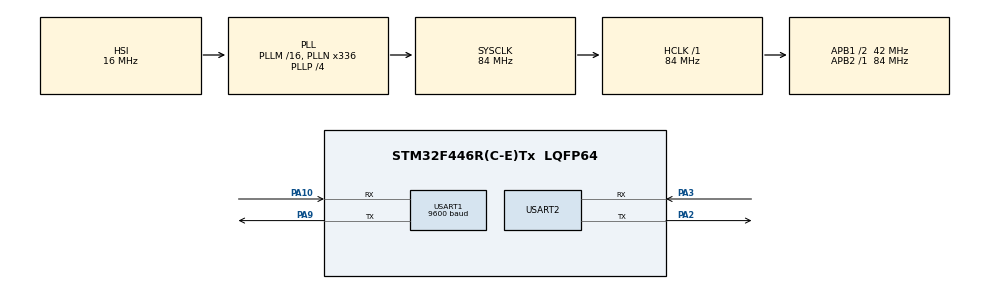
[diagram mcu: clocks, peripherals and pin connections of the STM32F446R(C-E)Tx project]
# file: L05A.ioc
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Mcu.Family=STM32F4
Mcu.Name=STM32F446R(C-E)Tx
Mcu.Package=LQFP64
NVIC.PriorityGroup=NVIC_PRIORITYGROUP_4
NVIC.USART1_IRQn=true\:0\:0\:false\:false\:true\:true\:true\:true
NVIC.USART2_IRQn=true\:3\:0\:true\:false\:true\:true\:true\:true
PA10.GPIO_PuPd=GPIO_PULLUP
PA10.Mode=Asynchronous
PA10.Signal=USART1_RX
PA2.Mode=Asynchronous
PA2.Signal=USART2_TX
PA3.GPIO_PuPd=GPIO_PULLUP
PA3.Mode=Asynchronous
PA3.Signal=USART2_RX
PA9.GPIO_PuPd=GPIO_PULLUP
PA9.Mode=Asynchronous
PA9.Signal=USART1_TX
ProjectManager.HeapSize=0x200
ProjectManager.StackSize=0x400
ProjectManager.TargetToolchain=STM32CubeIDE
RCC.AHBFreq_Value=84000000
RCC.APB1CLKDivider=RCC_HCLK_DIV2
RCC.APB1Freq_Value=42000000
RCC.APB1TimFreq_Value=84000000
RCC.APB2Freq_Value=84000000
RCC.APB2TimFreq_Value=84000000
RCC.CortexFreq_Value=84000000
RCC.FLatency-AdvancedSettings=FLASH_LATENCY_2
RCC.HCLKFreq_Value=84000000
RCC.HSE_VALUE=8000000
RCC.HSI_VALUE=16000000
RCC.LSE_VALUE=32768
RCC.PLLN=336
RCC.PLLP=RCC_PLLP_DIV4
RCC.SYSCLKFreq_VALUE=84000000
RCC.SYSCLKSource=RCC_SYSCLKSOURCE_PLLCLK
RCC.USBFreq_Value=168000000
RCC.VCOOutputFreq_Value=336000000
USART1.BaudRate=9600
USART1.VirtualMode=VM_ASYNC
USART2.VirtualMode=VM_ASYNC
board=NUCLEO-F446RE

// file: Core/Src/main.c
/* USER CODE BEGIN Header */
/**
  ******************************************************************************
  * @file           : main.c
  * @brief          : Main program body
  ******************************************************************************
  * @attention
  *
  * Copyright (c) 2025 STMicroelectronics.
  * All rights reserved.
  *
  * This software is licensed under terms that can be found in the LICENSE file
  * in the root directory of this software component.
  * If no LICENSE file comes with this software, it is provided AS-IS.
  *
  ******************************************************************************
  */
/* USER CODE END Header */
#include "main.h"

/* USER CODE BEGIN Includes */
#include <stdio.h>
#include <string.h>

/* USER CODE END Includes */

UART_HandleTypeDef huart1;
UART_HandleTypeDef huart2;

/* USER CODE BEGIN PV */

char chRFTXBuffer[100];

uint8_t ui8RX1, ui8RX2;

/* USER CODE END PV */

void SystemClock_Config(void);
static void MX_GPIO_Init(void);
static void MX_USART1_UART_Init(void);
static void MX_USART2_UART_Init(void);

int main(void)
{

  /* MCU Configuration--------------------------------------------------------*/

  /* Reset of all peripherals, Initializes the Flash interface and the Systick. */
  HAL_Init();

  /* Configure the system clock */
  SystemClock_Config();

  /* Initialize all configured peripherals */
  MX_GPIO_Init();
  MX_USART1_UART_Init();
  MX_USART2_UART_Init();
  /* USER CODE BEGIN 2 */

  HAL_UART_Receive_IT(&huart1, &ui8RX1, 1);
  HAL_UART_Receive_IT(&huart2, &ui8RX2, 1);

  /* USER CODE END 2 */

  /* Infinite loop */
  /* USER CODE BEGIN WHILE */
  while (1)
  {
	  //sprintf(chRFTXBuffer,"Message from Arthur\r\n");
	  //HAL_UART_Transmit_IT(&huart1, (uint8_t*)chRFTXBuffer, strlen(chRFTXBuffer));
	  HAL_Delay(1000);

    /* USER CODE END WHILE */

  }
}

void SystemClock_Config(void)
{
  RCC_OscInitTypeDef RCC_OscInitStruct = {0};
  RCC_ClkInitTypeDef RCC_ClkInitStruct = {0};

  /** Configure the main internal regulator output voltage
  */
  __HAL_RCC_PWR_CLK_ENABLE();
  __HAL_PWR_VOLTAGESCALING_CONFIG(PWR_REGULATOR_VOLTAGE_SCALE3);

  /** Initializes the RCC Oscillators according to the specified parameters
  * in the RCC_OscInitTypeDef structure.
  */
  RCC_OscInitStruct.OscillatorType = RCC_OSCILLATORTYPE_HSI;
  RCC_OscInitStruct.HSIState = RCC_HSI_ON;
  RCC_OscInitStruct.HSICalibrationValue = RCC_HSICALIBRATION_DEFAULT;
  RCC_OscInitStruct.PLL.PLLState = RCC_PLL_ON;
  RCC_OscInitStruct.PLL.PLLSource = RCC_PLLSOURCE_HSI;
  RCC_OscInitStruct.PLL.PLLM = 16;
  RCC_OscInitStruct.PLL.PLLN = 336;
  RCC_OscInitStruct.PLL.PLLP = RCC_PLLP_DIV4;
  RCC_OscInitStruct.PLL.PLLQ = 2;
  RCC_OscInitStruct.PLL.PLLR = 2;
  if (HAL_RCC_OscConfig(&RCC_OscInitStruct) != HAL_OK)
  {
    Error_Handler();
  }

  /** Initializes the CPU, AHB and APB buses clocks
  */
  RCC_ClkInitStruct.ClockType = RCC_CLOCKTYPE_HCLK|RCC_CLOCKTYPE_SYSCLK
                              |RCC_CLOCKTYPE_PCLK1|RCC_CLOCKTYPE_PCLK2;
  RCC_ClkInitStruct.SYSCLKSource = RCC_SYSCLKSOURCE_PLLCLK;
  RCC_ClkInitStruct.AHBCLKDivider = RCC_SYSCLK_DIV1;
  RCC_ClkInitStruct.APB1CLKDivider = RCC_HCLK_DIV2;
  RCC_ClkInitStruct.APB2CLKDivider = RCC_HCLK_DIV1;

  if (HAL_RCC_ClockConfig(&RCC_ClkInitStruct, FLASH_LATENCY_2) != HAL_OK)
  {
    Error_Handler();
  }
}

static void MX_USART1_UART_Init(void)
{

  huart1.Instance = USART1;
  huart1.Init.BaudRate = 9600;
  huart1.Init.WordLength = UART_WORDLENGTH_8B;
  huart1.Init.StopBits = UART_STOPBITS_1;
  huart1.Init.Parity = UART_PARITY_NONE;
  huart1.Init.Mode = UART_MODE_TX_RX;
  huart1.Init.HwFlowCtl = UART_HWCONTROL_NONE;
  huart1.Init.OverSampling = UART_OVERSAMPLING_16;
  if (HAL_UART_Init(&huart1) != HAL_OK)
  {
    Error_Handler();
  }

}

static void MX_USART2_UART_Init(void)
{

  huart2.Instance = USART2;
  huart2.Init.BaudRate = 115200;
  huart2.Init.WordLength = UART_WORDLENGTH_8B;
  huart2.Init.StopBits = UART_STOPBITS_1;
  huart2.Init.Parity = UART_PARITY_NONE;
  huart2.Init.Mode = UART_MODE_TX_RX;
  huart2.Init.HwFlowCtl = UART_HWCONTROL_NONE;
  huart2.Init.OverSampling = UART_OVERSAMPLING_16;
  if (HAL_UART_Init(&huart2) != HAL_OK)
  {
    Error_Handler();
  }

}

static void MX_GPIO_Init(void)
{

  /* GPIO Ports Clock Enable */
  __HAL_RCC_GPIOA_CLK_ENABLE();

}

/* USER CODE BEGIN 4 */

void HAL_UART_RxCpltCallback(UART_HandleTypeDef *huart)
{
  /* Prevent unused argument(s) compilation warning */
  //UNUSED(huart);
  /* NOTE: This function should not be modified, when the callback is needed,
           the HAL_UART_RxCpltCallback could be implemented in the user file
   */

	if(huart->Instance == huart1.Instance)
	{
		// RF -> PC
		HAL_UART_Transmit(&huart2, &ui8RX1, 1, 100);
		HAL_UART_Receive_IT(&huart1, &ui8RX1, 1);
	}
	else
	{
		// PC -> RF
		HAL_UART_Transmit(&huart1, &ui8RX2, 1, 100);
		HAL_UART_Receive_IT(&huart2, &ui8RX2, 1);
	}
}

/* USER CODE END 4 */

void Error_Handler(void)
{
  __disable_irq();
  while (1)
  {
  }
}
